# CC2650F128 register map
File version: 1.0
CPU: Cortex_M3 1.0, other endian, MPU, FPU, 3 interrupt priority bits
Registers are 32-bit, read-write, reset 0x0 unless marked. A register's access mark holds for its fields unless they carry their own. Offsets are from the block's base; [hi:lo] are bit positions.

## AUX_SCE — AUX Sensor Control Engine Control Module
Base 0x400E1000
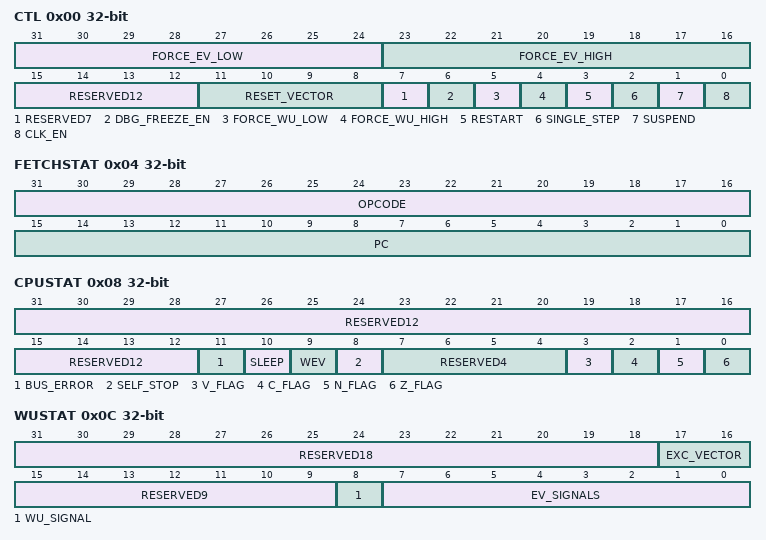
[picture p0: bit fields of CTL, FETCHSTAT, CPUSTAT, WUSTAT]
0x00 CTL — Internal. Only to be used through TI provided API.
  [31:24] FORCE_EV_LOW — [31:24] Internal. Only to be used through TI provided API.
  [23:16] FORCE_EV_HIGH — [23:16] Internal. Only to be used through TI provided API.
  [15:12] RESERVED12 — [15:12] Internal. Only to be used through TI provided API.
  [11:8] RESET_VECTOR — [11:8] Internal. Only to be used through TI provided API.
  [7] RESERVED7 — [7:7] Internal. Only to be used through TI provided API.
  [6] DBG_FREEZE_EN — [6:6] Internal. Only to be used through TI provided API.
  [5] FORCE_WU_LOW — [5:5] Internal. Only to be used through TI provided API.
  [4] FORCE_WU_HIGH — [4:4] Internal. Only to be used through TI provided API.
  [3] RESTART — [3:3] Internal. Only to be used through TI provided API.
  [2] SINGLE_STEP — [2:2] Internal. Only to be used through TI provided API.
  [1] SUSPEND — [1:1] Internal. Only to be used through TI provided API.
  [0] CLK_EN — [0:0] Internal. Only to be used through TI provided API.
0x04 FETCHSTAT — Internal. Only to be used through TI provided API.
  [31:16] OPCODE — [31:16] Internal. Only to be used through TI provided API.
  [15:0] PC — [15:0] Internal. Only to be used through TI provided API.
0x08 CPUSTAT — Internal. Only to be used through TI provided API.
  [31:12] RESERVED12 — [31:12] Internal. Only to be used through TI provided API.
  [11] BUS_ERROR — [11:11] Internal. Only to be used through TI provided API.
  [10] SLEEP — [10:10] Internal. Only to be used through TI provided API.
  [9] WEV — [9:9] Internal. Only to be used through TI provided API.
  [8] SELF_STOP — [8:8] Internal. Only to be used through TI provided API.
  [7:4] RESERVED4 — [7:4] Internal. Only to be used through TI provided API.
  [3] V_FLAG — [3:3] Internal. Only to be used through TI provided API.
  [2] C_FLAG — [2:2] Internal. Only to be used through TI provided API.
  [1] N_FLAG — [1:1] Internal. Only to be used through TI provided API.
  [0] Z_FLAG — [0:0] Internal. Only to be used through TI provided API.
0x0C WUSTAT — Internal. Only to be used through TI provided API.
  [31:18] RESERVED18 — [31:18] Internal. Only to be used through TI provided API.
  [17:16] EXC_VECTOR — [17:16] Internal. Only to be used through TI provided API.
  [15:9] RESERVED9 — [15:9] Internal. Only to be used through TI provided API.
  [8] WU_SIGNAL — [8:8] Internal. Only to be used through TI provided API.
  [7:0] EV_SIGNALS — [7:0] Internal. Only to be used through TI provided API.
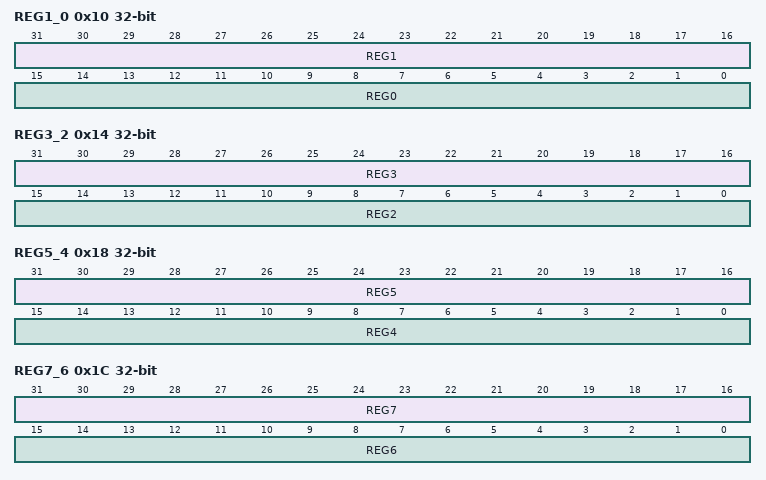
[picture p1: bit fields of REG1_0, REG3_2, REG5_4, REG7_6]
0x10 REG1_0 — Internal. Only to be used through TI provided API.
  [31:16] REG1 — [31:16] Internal. Only to be used through TI provided API.
  [15:0] REG0 — [15:0] Internal. Only to be used through TI provided API.
0x14 REG3_2 — Internal. Only to be used through TI provided API.
  [31:16] REG3 — [31:16] Internal. Only to be used through TI provided API.
  [15:0] REG2 — [15:0] Internal. Only to be used through TI provided API.
0x18 REG5_4 — Internal. Only to be used through TI provided API.
  [31:16] REG5 — [31:16] Internal. Only to be used through TI provided API.
  [15:0] REG4 — [15:0] Internal. Only to be used through TI provided API.
0x1C REG7_6 — Internal. Only to be used through TI provided API.
  [31:16] REG7 — [31:16] Internal. Only to be used through TI provided API.
  [15:0] REG6 — [15:0] Internal. Only to be used through TI provided API.
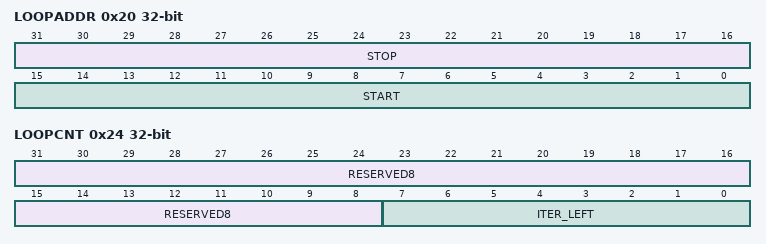
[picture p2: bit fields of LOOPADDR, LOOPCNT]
0x20 LOOPADDR — Internal. Only to be used through TI provided API.
  [31:16] STOP — [31:16] Internal. Only to be used through TI provided API.
  [15:0] START — [15:0] Internal. Only to be used through TI provided API.
0x24 LOOPCNT — Internal. Only to be used through TI provided API.
  [31:8] RESERVED8 — [31:8] Internal. Only to be used through TI provided API.
  [7:0] ITER_LEFT — [7:0] Internal. Only to be used through TI provided API.
